VERSION "1.0"

NS_ :

BS_:
BU_:

CM_ "RVC DBC File
Author: Dominique Parolin
for Winnebago Industries Inc.
";

BO_ 2583690496 DC_SOURCE_STATUS_1: 8 Vector__XXX
    SG_ Instance : 0|8@1+ (1,0) [0|255] "NA" Vector__XXX
    SG_ Device_Priority :     8|8@1+  (1,0)   [0|255]     "NA"  Vector__XXX
    SG_ DC_Voltage :     16|16@1+    (0.05,0)    [0|65535]   "V"     Vector__XXX
    SG_ DC_Current :     32|32@1-    (0.001,-2000000)   [0|4294967295]   "A"     Vector__XXX

    0 "Invalid"
    1 "Main House Battery Bank"
    2 "Chassis Start Battery"
    3 "Secondary House Battery Bank"
    4 "Generator Starter Battery"
    5 "Arbitrary";

    120 "Battery SOC/BMS device"
    100 "Inverter/Charger"
    80 "Charger"
    60 "Inverter"
    40 "Voltmeter/Ammeter"
    20 "Voltmeter"
    0 "No priority, always reporting";

    4294967295 "NA";

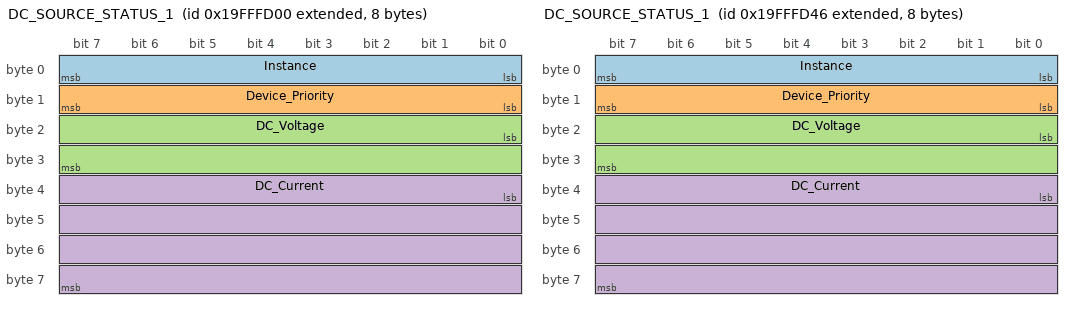
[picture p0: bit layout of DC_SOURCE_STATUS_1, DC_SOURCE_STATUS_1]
BO_ 2583690566 DC_SOURCE_STATUS_1: 8 Vector__XXX
    SG_ Instance : 0|8@1+ (1,0) [0|255] "NA" Vector__XXX
    SG_ Device_Priority :     8|8@1+  (1,0)   [0|255]     "NA"  Vector__XXX
    SG_ DC_Voltage :     16|16@1+    (0.05,0)    [0|65535]   "V"     Vector__XXX
    SG_ DC_Current :     32|32@1-    (0.001,-2000000)   [0|4294967295]   "A"     Vector__XXX

    0 "Invalid"
    1 "Main House Battery Bank - Lithionics"
    2 "Chassis Start Battery"
    3 "Secondary House Battery Bank"
    4 "Generator Starter Battery"
    5 "Arbitrary";

    120 "Battery SOC/BMS device"
    100 "Inverter/Charger"
    80 "Charger"
    60 "Inverter"
    40 "Voltmeter/Ammeter"
    20 "Voltmeter"
    0 "No priority, always reporting";

    4294967295 "NA";

BO_ 2583690240 DC_SOURCE_STATUS_2: 8 Vector__XXX
    SG_ DC_Instance :     0|8@1+  (1,0)   [0|255]     "NA"  Vector__XXX
    SG_ Device_Priority :     8|8@1+  (1,0)   [0|255]     "NA"  Vector__XXX
    SG_ Source_Temperature :     16|16@1+    (0.03125,-273)    [0|65535]   "deg C"     Vector__XXX
    SG_ State_Of_Charge :     32|8@1+    (0.5,0)   [0|255]   "%"     Vector__XXX
    SG_ Time_Remaining :     40|16@1+    (1,0)   [0|65535]   "Minutes"     Vector__XXX
    SG_ Time_Remaining_Interpretation :     56|2@1+     (1,0)   [0|3]   "NA"    Vector__XXX

    0 "Invalid"
    1 "Main House Battery Bank"
    2 "Chassis Start Battery"
    3 "Secondary House Battery Bank"
    4 "Generator Starter Battery"
    5 "Arbitrary";

    120 "Battery SOC/BMS device"
    100 "Inverter/Charger"
    80 "Charger"
    60 "Inverter"
    40 "Voltmeter/Ammeter"
    20 "Voltmeter"
    0 "No priority, always reporting";

    0 "Time to Empty"
    1 "Time to Full"
    3 "NA - Implicit time to empty";

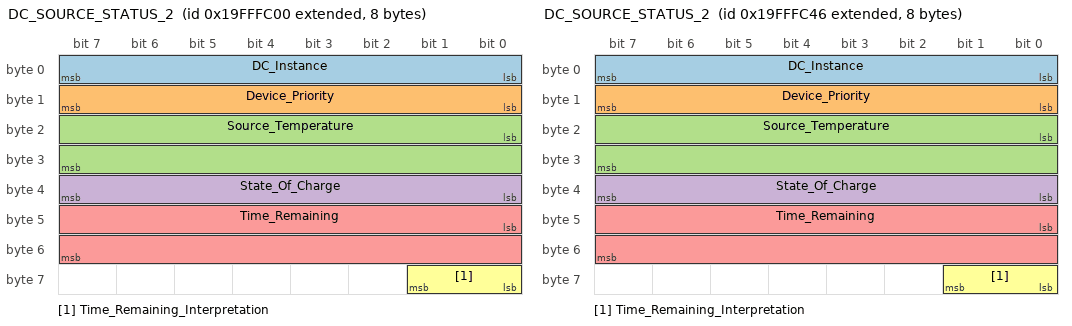
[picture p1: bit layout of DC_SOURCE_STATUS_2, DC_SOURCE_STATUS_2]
BO_ 2583690310 DC_SOURCE_STATUS_2: 8 Vector__XXX
    SG_ DC_Instance :     0|8@1+  (1,0)   [0|255]     "NA"  Vector__XXX
    SG_ Device_Priority :     8|8@1+  (1,0)   [0|255]     "NA"  Vector__XXX
    SG_ Source_Temperature :     16|16@1+    (0.03125,-273)    [0|65535]   "deg C"     Vector__XXX
    SG_ State_Of_Charge :     32|8@1+    (0.5,0)   [0|255]   "%"     Vector__XXX
    SG_ Time_Remaining :     40|16@1+    (1,0)   [0|65535]   "Minutes"     Vector__XXX
    SG_ Time_Remaining_Interpretation :     56|2@1+     (1,0)   [0|3]   "NA"    Vector__XXX

    0 "Invalid"
    1 "Main House Battery Bank"
    2 "Chassis Start Battery"
    3 "Secondary House Battery Bank"
    4 "Generator Starter Battery"
    5 "Arbitrary";

    120 "Battery SOC/BMS device"
    100 "Inverter/Charger"
    80 "Charger"
    60 "Inverter"
    40 "Voltmeter/Ammeter"
    20 "Voltmeter"
    0 "No priority, always reporting";

    0 "Time to Empty"
    1 "Time to Full"
    3 "NA - Implicit time to empty";

BO_ 2566881280 PROP_BMS_STATUS_1: 8 Vector__XXX
    SG_ DC_Instance : 0|8@1+  (1,0)   [0|255]     "NA"  Vector__XXX
    SG_ Number_Modules_Sensors : 8|8@1+  (1,0)   [0|255]     "#"  Vector__XXX
    SG_ BMS_Internal_Temp : 16|8@1+  (1,-40)   [0|255]     "deg C"  Vector__XXX
    SG_ Max_Recorded_Temp : 24|8@1+  (1,-40)   [0|255]     "deg C"  Vector__XXX
    SG_ Min_Recorded_Temp : 32|8@1+  (1,-40)   [0|255]     "deg C"  Vector__XXX
    SG_ BMS_Status_Code_1 : 40|8@1+  (1,0)   [0|255]     "BitMask"  Vector__XXX
    SG_ BMS_Status_Code_2 : 48|8@1+  (1,0)   [0|255]     "BitMask"  Vector__XXX
    SG_ BMS_Status_Code_3 : 56|8@1+  (1,0)   [0|255]     "BitMask"  Vector__XXX

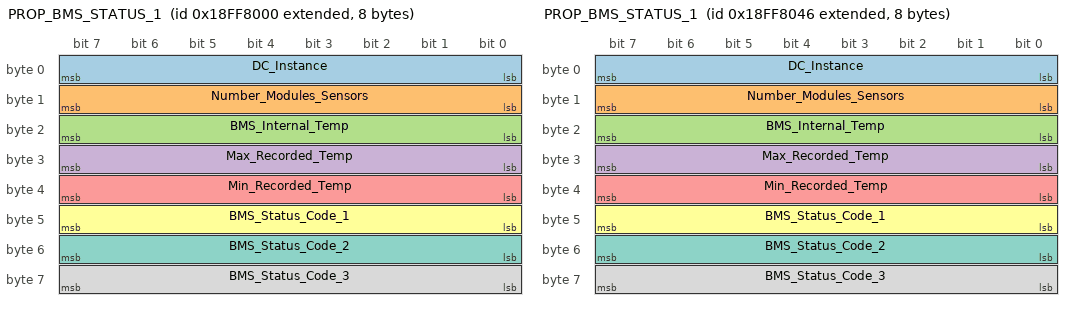
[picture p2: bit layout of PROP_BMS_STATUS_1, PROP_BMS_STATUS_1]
BO_ 2566881350 PROP_BMS_STATUS_1: 8 Vector__XXX
    SG_ DC_Instance : 0|8@1+  (1,0)   [0|255]     "NA"  Vector__XXX
    SG_ Number_Modules_Sensors : 8|8@1+  (1,0)   [0|255]     "#"  Vector__XXX
    SG_ BMS_Internal_Temp : 16|8@1+  (1,-40)   [0|255]     "deg C"  Vector__XXX
    SG_ Max_Recorded_Temp : 24|8@1+  (1,-40)   [0|255]     "deg C"  Vector__XXX
    SG_ Min_Recorded_Temp : 32|8@1+  (1,-40)   [0|255]     "deg C"  Vector__XXX
    SG_ BMS_Status_Code_1 : 40|8@1+  (1,0)   [0|255]     "BitMask"  Vector__XXX
    SG_ BMS_Status_Code_2 : 48|8@1+  (1,0)   [0|255]     "BitMask"  Vector__XXX
    SG_ BMS_Status_Code_3 : 56|8@1+  (1,0)   [0|255]     "BitMask"  Vector__XXX

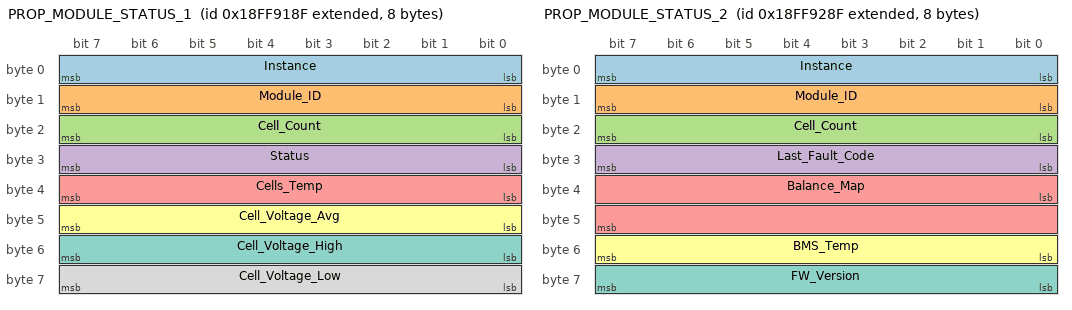
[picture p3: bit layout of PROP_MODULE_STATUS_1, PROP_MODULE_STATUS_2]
BO_ 2566885775 PROP_MODULE_STATUS_1: 8  Vector__XXX
    SG_ Instance : 0|8@1+ (1,0) [0|255] "#" Vector__XXX
    SG_ Module_ID : 8|8@1+ (1,0)   [0|255]     "#" Vector__XXX
    SG_ Cell_Count : 16|8@1+ (1,0)   [0|255]     "#" Vector__XXX
    SG_ Status : 24|8@1+ (1,0) [0|255]     ""  Vector__XXX
    SG_ Cells_Temp : 32|8@1+ (1,-40) [0|210]     "C"  Vector__XXX
    SG_ Cell_Voltage_Avg : 40|8@1+ (1,0) [0|250]   "V"  Vector__XXX
    SG_ Cell_Voltage_High : 48|8@1+ (1,0) [0|250]   "V"  Vector__XXX
    SG_ Cell_Voltage_Low : 56|8@1+ (1,0) [0|250]   "V"  Vector__XXX

BO_ 2566886031 PROP_MODULE_STATUS_2: 8  Vector__XXX
    SG_ Instance :     0|8@1+  (1,0)   [0|255]     "#" Vector__XXX
    SG_ Module_ID :     8|8@1+  (1,0)   [0|255]     "#" Vector__XXX
    SG_ Cell_Count :     16|8@1+  (1,0)   [0|255]     "#" Vector__XXX
    SG_ Last_Fault_Code :     24|8@1+ (1,0)   [0|255]     ""  Vector__XXX
    SG_ Balance_Map :     32|16@1+ (1,0)   [0|65535]     ""  Vector__XXX
    SG_ BMS_Temp :     48|8@1+ (1,-40)    [-40|210]   "C"  Vector__XXX
    SG_ FW_Version :     56|8@1+ (1,0)  [0|255] ""  Vector__XXX

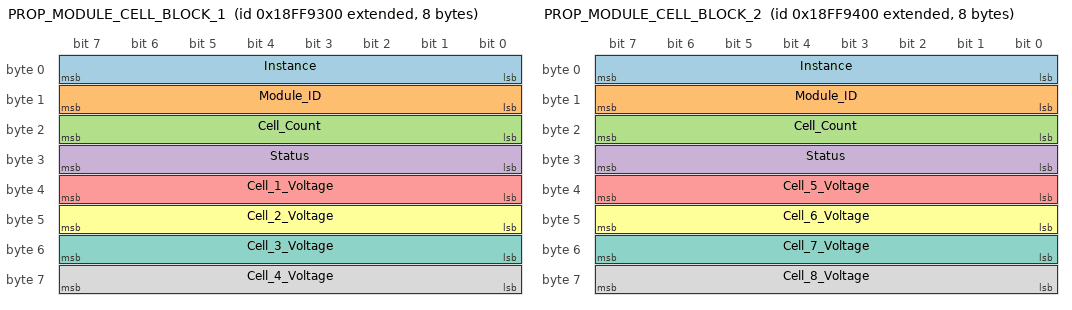
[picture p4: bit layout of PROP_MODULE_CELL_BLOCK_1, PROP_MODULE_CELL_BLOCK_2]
BO_ 2566886144 PROP_MODULE_CELL_BLOCK_1: 8  Vector__XXX
    SG_ Instance :     0|8@1+  (1,0)   [0|255]     "#" Vector__XXX
    SG_ Module_ID :     8|8@1+  (1,0)   [0|255]     "#" Vector__XXX
    SG_ Cell_Count :     16|8@1+  (1,0)   [0|255]     "#" Vector__XXX
    SG_ Status :     24|8@1+ (1,0)   [0|255]     ""  Vector__XXX
    SG_ Cell_1_Voltage :     32|8@1+ (1,0)    [0|250]   "V"  Vector__XXX
    SG_ Cell_2_Voltage :     40|8@1+ (1,0)    [0|250]   "V"  Vector__XXX
    SG_ Cell_3_Voltage :     48|8@1+ (1,0)    [0|250]   "V"  Vector__XXX
    SG_ Cell_4_Voltage :     56|8@1+ (1,0)    [0|250]   "V"  Vector__XXX

BO_ 2566886400 PROP_MODULE_CELL_BLOCK_2: 8  Vector__XXX
    SG_ Instance :     0|8@1+  (1,0)   [0|255]     "#" Vector__XXX
    SG_ Module_ID :     8|8@1+  (1,0)   [0|255]     "#" Vector__XXX
    SG_ Cell_Count :     16|8@1+  (1,0)   [0|255]     "#" Vector__XXX
    SG_ Status :     24|8@1+ (1,0)   [0|255]     ""  Vector__XXX
    SG_ Cell_5_Voltage :     32|8@1+ (1,0)    [0|250]   "V"  Vector__XXX
    SG_ Cell_6_Voltage :     40|8@1+ (1,0)    [0|250]   "V"  Vector__XXX
    SG_ Cell_7_Voltage :     48|8@1+ (1,0)    [0|250]   "V"  Vector__XXX
    SG_ Cell_8_Voltage :     56|8@1+ (1,0)    [0|250]   "V"  Vector__XXX

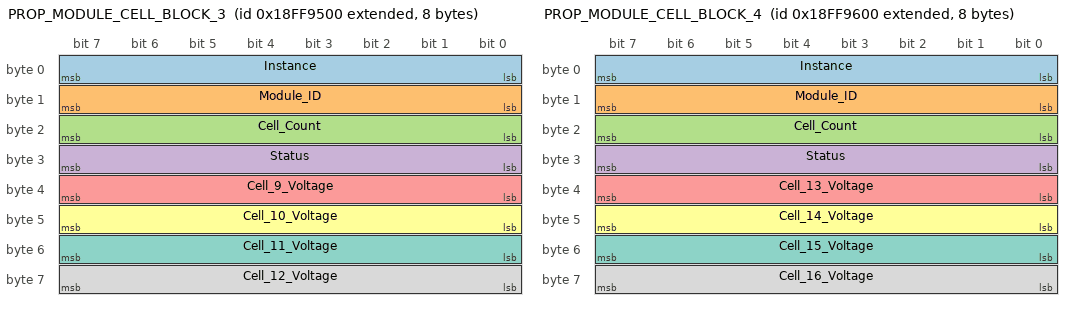
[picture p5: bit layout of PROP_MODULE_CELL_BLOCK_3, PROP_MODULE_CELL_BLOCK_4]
BO_ 2566886656 PROP_MODULE_CELL_BLOCK_3: 8  Vector__XXX
    SG_ Instance :     0|8@1+  (1,0)   [0|255]     "#" Vector__XXX
    SG_ Module_ID :     8|8@1+  (1,0)   [0|255]     "#" Vector__XXX
    SG_ Cell_Count :     16|8@1+  (1,0)   [0|255]     "#" Vector__XXX
    SG_ Status :     24|8@1+ (1,0)   [0|255]     ""  Vector__XXX
    SG_ Cell_9_Voltage :     32|8@1+ (1,0)    [0|250]   "V"  Vector__XXX
    SG_ Cell_10_Voltage :     40|8@1+ (1,0)    [0|250]   "V"  Vector__XXX
    SG_ Cell_11_Voltage :     48|8@1+ (1,0)    [0|250]   "V"  Vector__XXX
    SG_ Cell_12_Voltage :     56|8@1+ (1,0)    [0|250]   "V"  Vector__XXX

BO_ 2566886912 PROP_MODULE_CELL_BLOCK_4: 8  Vector__XXX
    SG_ Instance :     0|8@1+  (1,0)   [0|255]     "#" Vector__XXX
    SG_ Module_ID :     8|8@1+  (1,0)   [0|255]     "#" Vector__XXX
    SG_ Cell_Count :     16|8@1+  (1,0)   [0|255]     "#" Vector__XXX
    SG_ Status :     24|8@1+ (1,0)   [0|255]     ""  Vector__XXX
    SG_ Cell_13_Voltage :     32|8@1+ (1,0)    [0|250]   "V"  Vector__XXX
    SG_ Cell_14_Voltage :     40|8@1+ (1,0)    [0|250]   "V"  Vector__XXX
    SG_ Cell_15_Voltage :     48|8@1+ (1,0)    [0|250]   "V"  Vector__XXX
    SG_ Cell_16_Voltage :     56|8@1+ (1,0)    [0|250]   "V"  Vector__XXX

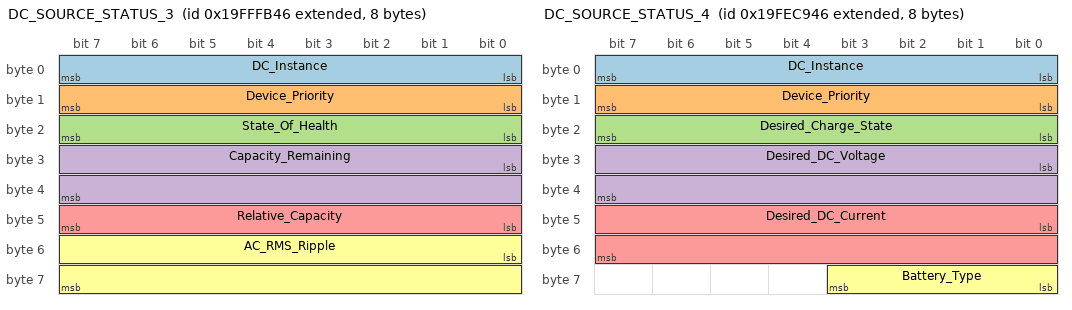
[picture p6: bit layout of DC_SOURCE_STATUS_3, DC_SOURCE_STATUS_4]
BO_ 2583690054 DC_SOURCE_STATUS_3: 8 Vector__XXX
    SG_ DC_Instance :     0|8@1+  (1,0)   [0|255]     "NA"  Vector__XXX
    SG_ Device_Priority :     8|8@1+  (1,0)   [0|255]     "NA"  Vector__XXX
    SG_ State_Of_Health :     16|8@1+  (0.5,0)   [0|255]     "%"  Vector__XXX
    SG_ Capacity_Remaining :     24|16@1+    (1,0)    [0|65535]   "Ah"     Vector__XXX
    SG_ Relative_Capacity :     40|8@1+    (0.5,0)   [0|255]   "%"     Vector__XXX
    SG_ AC_RMS_Ripple :     48|16@1+    (1,0)   [0|65535]   "mV"     Vector__XXX

BO_ 2583611718 DC_SOURCE_STATUS_4: 8 Vector__XXX
    SG_ DC_Instance :     0|8@1+  (1,0)   [0|255]     "NA"  Vector__XXX
    SG_ Device_Priority :     8|8@1+  (1,0)   [0|255]     "NA"  Vector__XXX
    SG_ Desired_Charge_State :     16|8@1+  (1,0)   [0|255]     "NA"  Vector__XXX
    SG_ Desired_DC_Voltage :     24|16@1+    (0.05,0)    [0|65535]   "V"     Vector__XXX
    SG_ Desired_DC_Current :     40|16@1+    (0.05,0)   [0|65535]   "A"     Vector__XXX
    SG_ Battery_Type :     56|4@1+    (1,0)   [0|15]   "NA"     Vector__XXX

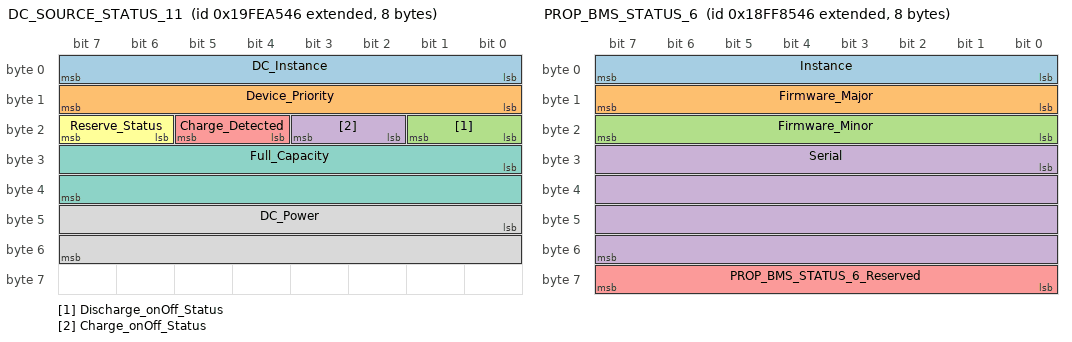
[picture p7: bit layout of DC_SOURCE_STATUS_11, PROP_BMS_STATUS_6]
BO_ 2583602502 DC_SOURCE_STATUS_11: 8 Vector__XXX
    SG_ DC_Instance :     0|8@1+  (1,0)   [0|255]     "NA"  Vector__XXX
    SG_ Device_Priority :     8|8@1+  (1,0)   [0|255]     "NA"  Vector__XXX
    SG_ Discharge_onOff_Status :     16|2@1+  (1,0)   [0|3]     "NA"  Vector__XXX
    SG_ Charge_onOff_Status :     18|2@1+  (1,0)   [0|3]     "NA"  Vector__XXX
    SG_ Charge_Detected :     20|2@1+  (1,0)   [0|3]     "NA"  Vector__XXX
    SG_ Reserve_Status :     22|2@1+  (1,0)   [0|3]     "NA"  Vector__XXX
    SG_ Full_Capacity :     24|16@1+    (1,0)   [0|65535]   "Ah"    Vector__XXX
    SG_ DC_Power :     40|16@1+    (1,0)   [0|65535]   "W" Vector__XXX

BO_ 2566882630 PROP_BMS_STATUS_6: 8 Vector__XXX
    SG_ Instance: 0|8@1+ (1,0) [0|255] "#" Vector__XXX
    SG_ Firmware_Major: 8|8@1+ (1,0) [0|255] "#" Vector__XXX
    SG_ Firmware_Minor: 16|8@1+ (1,0) [0|255] "#" Vector__XXX
    SG_ Serial: 24|32@1+ (1,0) [0|4228250625] "#" Vector__XXX
    SG_ PROP_BMS_STATUS_6_Reserved: 56|8@1+ (1,0) [0|255] "#" Vector__XXX
